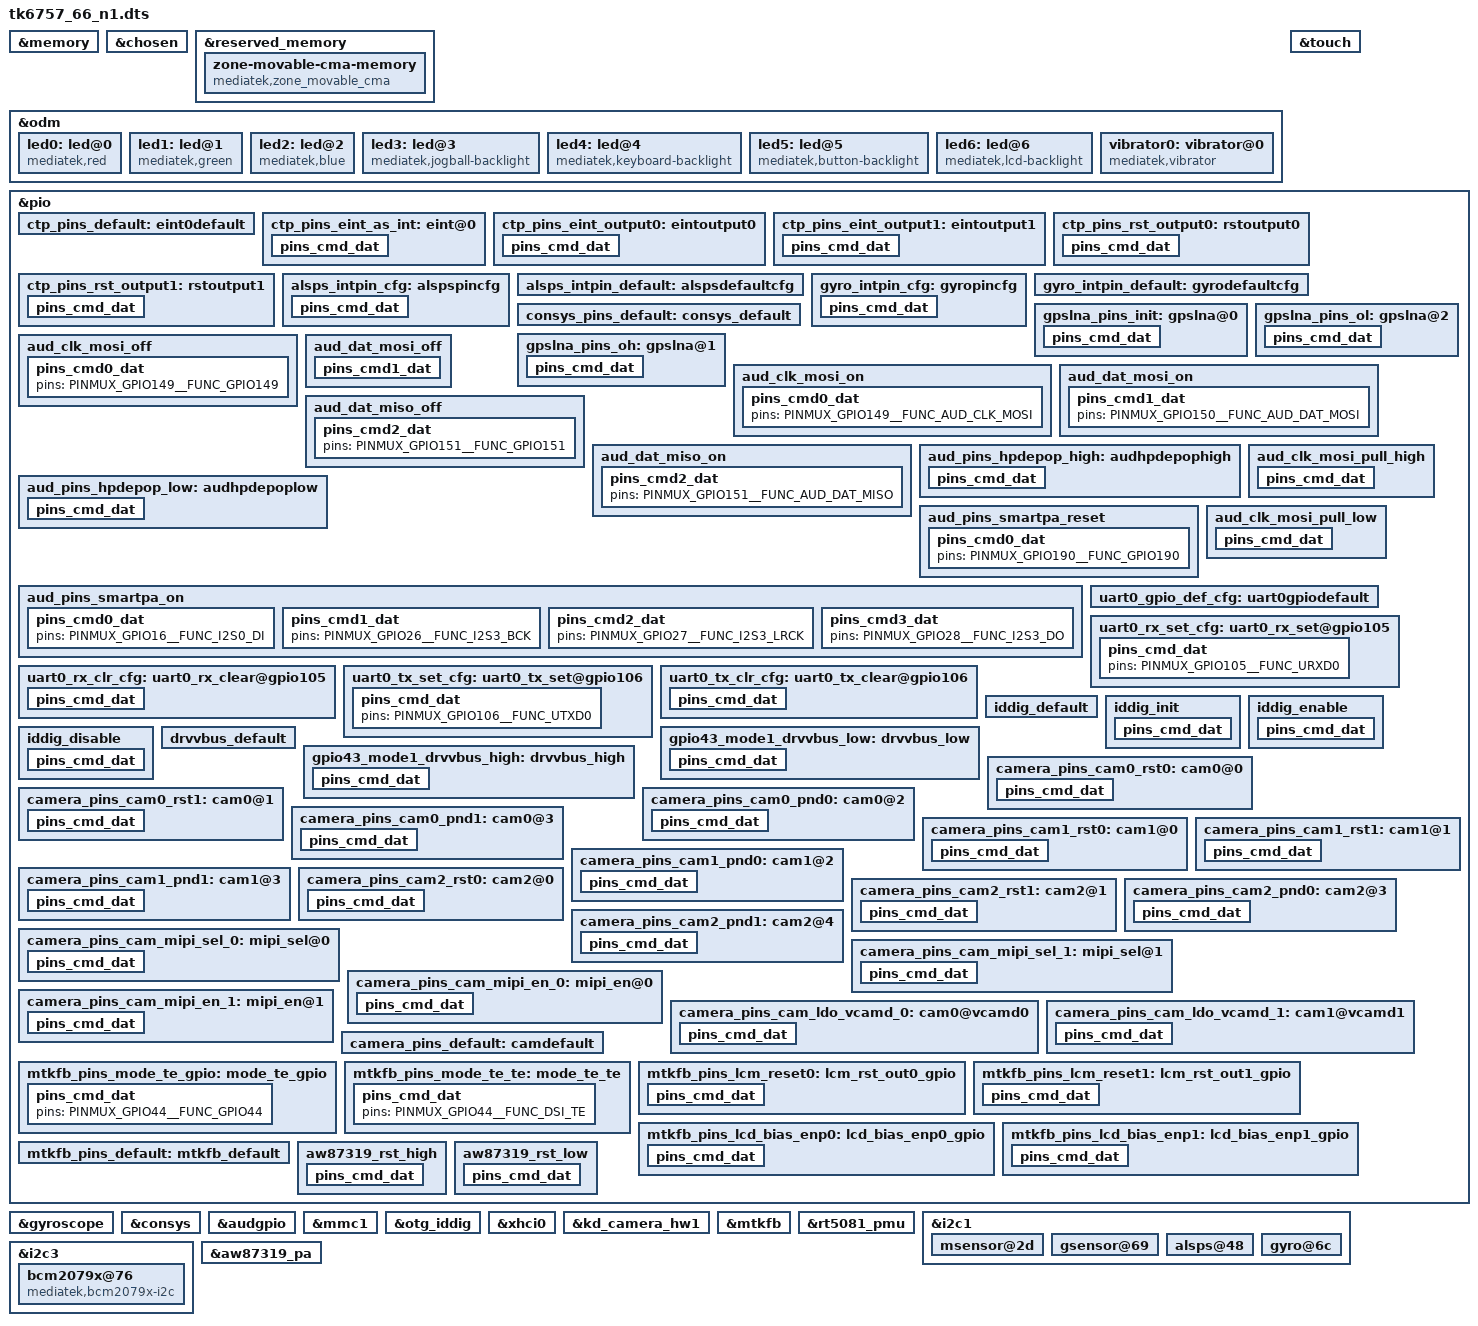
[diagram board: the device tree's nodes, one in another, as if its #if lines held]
#include <generated/autoconf.h>
/dts-v1/;

#ifdef CONFIG_MTK_DTBO_FEATURE
/plugin/;
#include <dt-bindings/interrupt-controller/irq.h>
#include <dt-bindings/interrupt-controller/arm-gic.h>
#include <dt-bindings/mmc/mt6757-msdc.h>
#include <dt-bindings/pinctrl/mt6757-pinfunc.h>
#else
#include "mt6757.dts"
#endif

&memory {
	device_type = "memory";
	reg = <0 0x40000000 0 0x1e605000>,
		  <1 0x00000000 0 0x20000000>;
};

/* chosen */
&chosen {
	bootargs = "console=tty0 console=ttyMT0,921600n1 root=/dev/ram initrd=0x45000000,
	0x1000000 loglevel=8 androidboot.selinux=permissive androidboot.hardware=mt6757";
	/* fpga may has no lk, we need to specify display info here */
	/* fb buffer is reserved using this dts by memory node above */
	atag,videolfb-fb_base_h = <0x0>;
	atag,videolfb-fb_base_l = <0x5e605000>;
	atag,videolfb-islcmfound = <1>;
	/* because no lk, so lcm is not inited */
	atag,videolfb-islcm_inited = <0>;
	atag,videolfb-fps= <6000>;
	atag,videolfb-vramSize= <0x017bb000>;
	atag,videolfb-lcmname= "nt35695_fhd_dsi_cmd_truly_nt50358_drv";
};

&reserved_memory {
	#address-cells = <2>;
	#size-cells = <2>;
	ranges;

	zone-movable-cma-memory {
		compatible = "mediatek,zone_movable_cma";
		size = <0 0xffc00000>;
		/* 256MB alignment */
		alignment = <0 0x10000000>;
		alloc-ranges = <0 0xc0000000 1 0x0>;
	};
};

&odm {
	led0:led@0 {
		compatible = "mediatek,red";
		led_mode = <3>;
		data = <1>;
		pwm_config = <0 0 0 0 0>;
	};
	led1:led@1 {
		compatible = "mediatek,green";
		led_mode = <3>;
		data = <2>;
		pwm_config = <0 0 0 0 0>;
	};
	led2:led@2 {
		compatible = "mediatek,blue";
		led_mode = <0>;
		data = <1>;
		pwm_config = <0 0 0 0 0>;
	};
	led3:led@3 {
		compatible = "mediatek,jogball-backlight";
		led_mode = <0>;
		data = <1>;
		pwm_config = <0 0 0 0 0>;
	};
	led4:led@4 {
		compatible = "mediatek,keyboard-backlight";
		led_mode = <0>;
		data = <1>;
		pwm_config = <0 0 0 0 0>;
	};
	led5:led@5 {
		compatible = "mediatek,button-backlight";
		led_mode = <0>;
		data = <1>;
		pwm_config = <0 0 0 0 0>;
	};
	led6:led@6 {
		compatible = "mediatek,lcd-backlight";
		led_mode = <5>;
		data = <1>;
		pwm_config = <0 0 0 0 0>;
	};
	vibrator0:vibrator@0 {
		compatible = "mediatek,vibrator";
		vib_timer = <25>;
		vib_limit = <9>;
		vib_vol= <9>;
	};


};

/* TOUCH start */
&touch {
	tpd-resolution = <1080 1920>;
	use-tpd-button = <0>;
	tpd-key-num = <3>;
	tpd-key-local = <139 172 158 0>;
	tpd-key-dim-local = <0x5a 0x373 0x64 0x28 0xe6 0x373 0x64 0x28 0x172 0x373 0x64 0x28 0x0 0x0 0x0 0x0>;
	tpd-max-touch-num = <5>;
	tpd-filter-enable = <1>;
	tpd-filter-pixel-density = <146>;
	tpd-filter-custom-prameters = <0 0 0 0 0 0 0 0 0 0 0 0>;
	tpd-filter-custom-speed = <0 0 0>;
	pinctrl-names = "default", "state_eint_as_int", "state_eint_output0", "state_eint_output1",
		"state_rst_output0", "state_rst_output1";
	pinctrl-0 = <&ctp_pins_default>;
	pinctrl-1 = <&ctp_pins_eint_as_int>;
	pinctrl-2 = <&ctp_pins_eint_output0>;
	pinctrl-3 = <&ctp_pins_eint_output1>;
	pinctrl-4 = <&ctp_pins_rst_output0>;
	pinctrl-5 = <&ctp_pins_rst_output1>;
	status = "okay";
};
&pio {
	ctp_pins_default: eint0default {
	};
	ctp_pins_eint_as_int: eint@0 {
		pins_cmd_dat {
			pins = <PINMUX_GPIO1__FUNC_GPIO1>;
			slew-rate = <0>;
			bias-disable;
		};
	};
	ctp_pins_eint_output0: eintoutput0 {
		pins_cmd_dat {
			pins = <PINMUX_GPIO1__FUNC_GPIO1>;
			slew-rate = <1>;
			output-low;
		};
	};
	ctp_pins_eint_output1: eintoutput1 {
		pins_cmd_dat {
			pins = <PINMUX_GPIO1__FUNC_GPIO1>;
			slew-rate = <1>;
			output-high;
		};
	};
	ctp_pins_rst_output0: rstoutput0 {
		pins_cmd_dat {
			pins = <PINMUX_GPIO42__FUNC_GPIO42>;
			slew-rate = <1>;
			output-low;
		};
	};
	ctp_pins_rst_output1: rstoutput1 {
		pins_cmd_dat {
			pins = <PINMUX_GPIO42__FUNC_GPIO42>;
			slew-rate = <1>;
			output-high;
		};
	};
};
/* TOUCH end */

/* sensor gpio standization */
&pio {
	alsps_intpin_cfg: alspspincfg {

		pins_cmd_dat {
			pins = <PINMUX_GPIO2__FUNC_GPIO2>;
			slew-rate = <0>;
			bias-pull-up = <0>;
		};
	};

	alsps_intpin_default: alspsdefaultcfg {

	};

	gyro_intpin_cfg: gyropincfg {

		pins_cmd_dat {
			pins = <PINMUX_GPIO0__FUNC_GPIO0>;
			slew-rate = <0>;
			bias-pull-down = <0>;
		};
	};

	gyro_intpin_default: gyrodefaultcfg {

	};
};


&gyroscope {
	pinctrl-names = "pin_default", "pin_cfg";
	pinctrl-0 = <&gyro_intpin_default>;
	pinctrl-1 = <&gyro_intpin_cfg>;
	status = "okay";
};
/* sensor end */

/* CONSYS GPIO standardization */
&pio {
	consys_pins_default: consys_default {
	};
	gpslna_pins_init: gpslna@0 {
		pins_cmd_dat {
			pins = <PINMUX_GPIO114__FUNC_GPIO114>;
			slew-rate = <0>;
			bias-disable;
			output-low;
		};
	};
	gpslna_pins_oh: gpslna@1 {
		pins_cmd_dat {
			pins = <PINMUX_GPIO114__FUNC_GPIO114>;
			slew-rate = <1>;
			output-high;
		};
	};
	gpslna_pins_ol: gpslna@2 {
		pins_cmd_dat {
			pins = <PINMUX_GPIO114__FUNC_GPIO114>;
			slew-rate = <1>;
			output-low;
		};
	};
};
&consys {
	pinctrl-names = "default", "gps_lna_state_init", "gps_lna_state_oh", "gps_lna_state_ol";
	pinctrl-0 = <&consys_pins_default>;
	pinctrl-1 = <&gpslna_pins_init>;
	pinctrl-2 = <&gpslna_pins_oh>;
	pinctrl-3 = <&gpslna_pins_ol>;
	status = "okay";
};
/* CONSYS end */

/* AUDIO GPIO standardization */
&audgpio {
	pinctrl-names = "aud_clk_mosi_off",
			"aud_clk_mosi_on",
			"aud_dat_mosi_off",
			"aud_dat_mosi_on",
			"aud_dat_miso_off",
			"aud_dat_miso_on",
			"hpdepop-pullhigh",
			"hpdepop-pulllow",
			"aud_smartpa_reset",
			"aud_smartpa_on",
			"aud_clk_mosi_pull_high",
			"aud_clk_mosi_pull_low";
	pinctrl-0 = <&aud_clk_mosi_off>;
	pinctrl-1 = <&aud_clk_mosi_on>;
	pinctrl-2 = <&aud_dat_mosi_off>;
	pinctrl-3 = <&aud_dat_mosi_on>;
	pinctrl-4 = <&aud_dat_miso_off>;
	pinctrl-5 = <&aud_dat_miso_on>;
	pinctrl-6 = <&aud_pins_hpdepop_high>;
	pinctrl-7 = <&aud_pins_hpdepop_low>;
	pinctrl-8 = <&aud_pins_smartpa_reset>;
	pinctrl-9 = <&aud_pins_smartpa_on>;
	pinctrl-10 = <&aud_clk_mosi_pull_high>;
	pinctrl-11 = <&aud_clk_mosi_pull_low>;
	status = "okay";
};

&pio {
	aud_clk_mosi_off: aud_clk_mosi_off {
		pins_cmd0_dat {
			pins = <PINMUX_GPIO149__FUNC_GPIO149>;
		};
	};

	aud_clk_mosi_on: aud_clk_mosi_on {
		pins_cmd0_dat {
			pins = <PINMUX_GPIO149__FUNC_AUD_CLK_MOSI>;
		};
	};

	aud_dat_mosi_off: aud_dat_mosi_off {
		pins_cmd1_dat {
			pins = <PINMUX_GPIO150__FUNC_GPIO150>;
			slew-rate = <0>;
			bias-pull-up = <0>;
		};
	};

	aud_dat_mosi_on: aud_dat_mosi_on {
		pins_cmd1_dat {
			pins = <PINMUX_GPIO150__FUNC_AUD_DAT_MOSI>;
		};
	};

	aud_dat_miso_off: aud_dat_miso_off {
		pins_cmd2_dat {
			pins = <PINMUX_GPIO151__FUNC_GPIO151>;
		};
	};

	aud_dat_miso_on: aud_dat_miso_on {
		pins_cmd2_dat {
			pins = <PINMUX_GPIO151__FUNC_AUD_DAT_MISO>;
		};
	};

	aud_pins_hpdepop_high: audhpdepophigh {
		pins_cmd_dat {
			pins = <PINMUX_GPIO24__FUNC_GPIO24>;
			slew-rate = <1>;
			output-high;
		};
	};

	aud_pins_hpdepop_low: audhpdepoplow {
		pins_cmd_dat {
			pins = <PINMUX_GPIO24__FUNC_GPIO24>;
			slew-rate = <1>;
			output-low;
		};
	};

	aud_pins_smartpa_reset: aud_pins_smartpa_reset {
		pins_cmd0_dat {
			pins = <PINMUX_GPIO190__FUNC_GPIO190>;
		};
	};

	aud_pins_smartpa_on: aud_pins_smartpa_on {
		pins_cmd0_dat {
			pins = <PINMUX_GPIO16__FUNC_I2S0_DI>;
		};
		pins_cmd1_dat {
			pins = <PINMUX_GPIO26__FUNC_I2S3_BCK>;
		};
		pins_cmd2_dat {
			pins = <PINMUX_GPIO27__FUNC_I2S3_LRCK>;
		};
		pins_cmd3_dat {
			pins = <PINMUX_GPIO28__FUNC_I2S3_DO>;
		};
	};

	aud_clk_mosi_pull_high: aud_clk_mosi_pull_high {
		pins_cmd_dat {
			pins = <PINMUX_GPIO149__FUNC_GPIO149>;
			slew-rate = <1>;
			output-high;
		};
	};

	aud_clk_mosi_pull_low: aud_clk_mosi_pull_low {
		pins_cmd_dat {
			pins = <PINMUX_GPIO149__FUNC_GPIO149>;
			slew-rate = <1>;
			output-low;
		};
	};
};
/* AUDIO end */

&mmc1 {
	status = "okay";
};

/* UART GPIO */
/*
*&apuart0 {
*	pinctrl-names = "uart0_gpio_default",
*			"uart0_rx_set",
*			"uart0_rx_clear",
*			"uart0_tx_set",
*			"uart0_tx_clear";
*	pinctrl-0 = <&uart0_gpio_def_cfg>;
*	pinctrl-1 = <&uart0_rx_set_cfg>;
*	pinctrl-2 = <&uart0_rx_clr_cfg>;
*	pinctrl-3 = <&uart0_tx_set_cfg>;
*	pinctrl-4 = <&uart0_tx_clr_cfg>;
*	status = "okay";
*};
*/
&pio {
	/* UART GPIO Settings - Start */
	/* UART0: rx set, rx clear, tx clear, tx clear*/
	uart0_gpio_def_cfg:uart0gpiodefault {

	};
	uart0_rx_set_cfg:uart0_rx_set@gpio105 {
		pins_cmd_dat {
			pins = <PINMUX_GPIO105__FUNC_URXD0>;
		};
	};
	uart0_rx_clr_cfg:uart0_rx_clear@gpio105  {
		pins_cmd_dat {
			pins = <PINMUX_GPIO105__FUNC_GPIO105>;
			slew-rate = <1>;
			output-high;
		};
	};
	uart0_tx_set_cfg:uart0_tx_set@gpio106  {
		pins_cmd_dat {
			pins = <PINMUX_GPIO106__FUNC_UTXD0>;
		};
	};
	uart0_tx_clr_cfg:uart0_tx_clear@gpio106  {
		pins_cmd_dat {
			pins = <PINMUX_GPIO106__FUNC_GPIO106>;
			slew-rate = <1>;
			output-high;
		};
	};
};/* UART GPIO end */

&pio {
	iddig_default: iddig_default {
	};
	iddig_init: iddig_init {
		pins_cmd_dat {
			pins = <PINMUX_GPIO42__FUNC_IDDIG>;
			input-enable;
			slew-rate = <0>;
			bias-pull-up = <0>;
		};
	};
	iddig_enable: iddig_enable {
		pins_cmd_dat {
			pins = <PINMUX_GPIO42__FUNC_IDDIG>;
			input-enable;
			slew-rate = <0>;
			bias-pull-up = <0>;
		};
	};
	iddig_disable: iddig_disable {
		pins_cmd_dat {
			pins = <PINMUX_GPIO42__FUNC_GPIO42>;
			input-disable;
			slew-rate = <1>;
			output-low;
		};
	};
};

&pio {
	drvvbus_default: drvvbus_default {
	};

	gpio43_mode1_drvvbus_low: drvvbus_low {
		pins_cmd_dat {
			pins = <PINMUX_GPIO43__FUNC_USB_DRVVBUS>;
			slew-rate = <1>;
			output-low;
		};
	};

	gpio43_mode1_drvvbus_high: drvvbus_high {
		pins_cmd_dat {
			pins = <PINMUX_GPIO43__FUNC_USB_DRVVBUS>;
			slew-rate = <1>;
			output-high;
		};
	};
};

&otg_iddig {
	pinctrl-names = "iddig_default", "iddig_init", "iddig_enable", "iddig_disable";
	pinctrl-0 = <&iddig_default>;
	pinctrl-1 = <&iddig_init>;
	pinctrl-2 = <&iddig_enable>;
	pinctrl-3 = <&iddig_disable>;
	status = "okay";
};

&xhci0 {
	pinctrl-names = "drvvbus_default", "drvvbus_low", "drvvbus_high";
	pinctrl-0 = <&drvvbus_default>;
	pinctrl-1 = <&gpio43_mode1_drvvbus_low>;
	pinctrl-2 = <&gpio43_mode1_drvvbus_high>;
	status = "okay";
};
/* CAMERA GPIO standardization */
&pio {
	camera_pins_cam0_rst0: cam0@0 {
		pins_cmd_dat {
			pins = <PINMUX_GPIO110__FUNC_GPIO110>;
			slew-rate = <1>; /*direction 0:in, 1:out*/
			output-low;/*direction out used only. output_low or high*/
		};
	};
	camera_pins_cam0_rst1: cam0@1 {
		pins_cmd_dat {
			pins = <PINMUX_GPIO110__FUNC_GPIO110>;
			slew-rate = <1>;
			output-high;
		};
	};
	camera_pins_cam0_pnd0: cam0@2 {
		pins_cmd_dat {
			pins = <PINMUX_GPIO107__FUNC_GPIO107>;
			slew-rate = <1>;
			output-low;
		};
	};
	camera_pins_cam0_pnd1: cam0@3 {
		pins_cmd_dat {
			pins = <PINMUX_GPIO107__FUNC_GPIO107>;
			slew-rate = <1>;
			output-high;
		};
	};
	camera_pins_cam1_rst0: cam1@0 {
		pins_cmd_dat {
			pins = <PINMUX_GPIO111__FUNC_GPIO111>;
			slew-rate = <1>; /*direction 0:in, 1:out*/
			output-low;/*direction out used only. output_low or high*/
		};
	};
	camera_pins_cam1_rst1: cam1@1 {
		pins_cmd_dat {
			pins = <PINMUX_GPIO111__FUNC_GPIO111>;
			slew-rate = <1>;
			output-high;
		};
	};
	camera_pins_cam1_pnd0: cam1@2 {
		pins_cmd_dat {
			pins = <PINMUX_GPIO108__FUNC_GPIO108>;
			slew-rate = <1>;
			output-low;
		};
	};
	camera_pins_cam1_pnd1: cam1@3 {
		pins_cmd_dat {
			pins = <PINMUX_GPIO108__FUNC_GPIO108>;
			slew-rate = <1>;
			output-high;
		};
	};
	camera_pins_cam2_rst0: cam2@0 {
		pins_cmd_dat {
			pins = <PINMUX_GPIO87__FUNC_GPIO87>;
			slew-rate = <1>;
			output-low;
		};
	};
	camera_pins_cam2_rst1: cam2@1 {
		pins_cmd_dat {
			pins = <PINMUX_GPIO87__FUNC_GPIO87>;
			slew-rate = <1>;
			output-high;
		};
	};
	camera_pins_cam2_pnd0: cam2@3 {
		pins_cmd_dat {
			pins = <PINMUX_GPIO85__FUNC_GPIO85>;
			slew-rate = <1>;
			output-low;
		};
	};
	camera_pins_cam2_pnd1: cam2@4 {
		pins_cmd_dat {
			pins = <PINMUX_GPIO85__FUNC_GPIO85>;
			slew-rate = <1>;
			output-high;
		};
	};
	camera_pins_cam_mipi_sel_0: mipi_sel@0 {
		pins_cmd_dat {
			pins = <PINMUX_GPIO102__FUNC_GPIO102>;
			slew-rate = <1>;
			output-low;
		};
	};
	camera_pins_cam_mipi_sel_1: mipi_sel@1 {
		pins_cmd_dat {
			pins = <PINMUX_GPIO102__FUNC_GPIO102>;
			slew-rate = <1>;
			output-high;
		};
	};
	camera_pins_cam_mipi_en_0: mipi_en@0 {
		pins_cmd_dat {
			pins = <PINMUX_GPIO10__FUNC_GPIO10>;
			slew-rate = <1>;
			output-low;
		};
	};
	camera_pins_cam_mipi_en_1: mipi_en@1 {
		pins_cmd_dat {
			pins = <PINMUX_GPIO10__FUNC_GPIO10>;
			slew-rate = <1>;
			output-high;
		};
	};
	camera_pins_cam_ldo_vcamd_0: cam0@vcamd0 {
		pins_cmd_dat {
			pins = <PINMUX_GPIO100__FUNC_GPIO100>;
			slew-rate = <1>;
			output-low;
		};
	};
	camera_pins_cam_ldo_vcamd_1: cam1@vcamd1 {
		pins_cmd_dat {
			pins = <PINMUX_GPIO100__FUNC_GPIO100>;
			slew-rate = <1>;
			output-high;
		};
	};
	camera_pins_default: camdefault {
	};

};

&kd_camera_hw1 {
	pinctrl-names = "default",
			"cam0_rst0", "cam0_rst1", "cam0_pnd0", "cam0_pnd1",
			"cam1_rst0", "cam1_rst1", "cam1_pnd0", "cam1_pnd1",
			"cam2_rst0", "cam2_rst1", "cam2_pnd0", "cam2_pnd1",
			"cam_mipi_switch_sel_0", "cam_mipi_switch_sel_1",
			"cam_mipi_switch_en_0", "cam_mipi_switch_en_1",
			"cam_ldo_vcamd_0", "cam_ldo_vcamd_1";

	pinctrl-0 = <&camera_pins_default>;
	pinctrl-1 = <&camera_pins_cam0_rst0>;
	pinctrl-2 = <&camera_pins_cam0_rst1>;
	pinctrl-3 = <&camera_pins_cam0_pnd0>;
	pinctrl-4 = <&camera_pins_cam0_pnd1>;
	pinctrl-5 = <&camera_pins_cam1_rst0>;
	pinctrl-6 = <&camera_pins_cam1_rst1>;
	pinctrl-7 = <&camera_pins_cam1_pnd0>;
	pinctrl-8 = <&camera_pins_cam1_pnd1>;
	pinctrl-9 = <&camera_pins_cam2_rst0>;
	pinctrl-10 = <&camera_pins_cam2_rst1>;
	pinctrl-11 = <&camera_pins_cam2_pnd0>;
	pinctrl-12 = <&camera_pins_cam2_pnd1>;
	pinctrl-13 = <&camera_pins_cam_mipi_sel_0>;
	pinctrl-14 = <&camera_pins_cam_mipi_sel_1>;
	pinctrl-15 = <&camera_pins_cam_mipi_en_0>;
	pinctrl-16 = <&camera_pins_cam_mipi_en_1>;
	pinctrl-17 = <&camera_pins_cam_ldo_vcamd_0>;
	pinctrl-18 = <&camera_pins_cam_ldo_vcamd_1>;
	status = "okay";

};
/* CAMERA GPIO end */

/* DISPSYS GPIO standardization */
&pio {

	mtkfb_pins_mode_te_gpio: mode_te_gpio {
		pins_cmd_dat {
			pins = <PINMUX_GPIO44__FUNC_GPIO44>;
		};
	};

	mtkfb_pins_mode_te_te: mode_te_te {
		pins_cmd_dat {
			pins = <PINMUX_GPIO44__FUNC_DSI_TE>;
		};
	};

	mtkfb_pins_lcm_reset0: lcm_rst_out0_gpio {
		pins_cmd_dat {
			pins = <PINMUX_GPIO158__FUNC_LCM_RST>;
			slew-rate = <1>;
			output-low;
		};
	};

	mtkfb_pins_lcm_reset1: lcm_rst_out1_gpio {
		pins_cmd_dat {
			pins = <PINMUX_GPIO158__FUNC_LCM_RST>;
			slew-rate = <1>;
			output-high;
		};
	};

	mtkfb_pins_lcd_bias_enp0: lcd_bias_enp0_gpio {
		pins_cmd_dat {
			pins = <PINMUX_GPIO21__FUNC_GPIO21>;
			slew-rate = <1>;
			output-low;
		};
	};

	mtkfb_pins_lcd_bias_enp1: lcd_bias_enp1_gpio {
		pins_cmd_dat {
			pins = <PINMUX_GPIO21__FUNC_GPIO21>;
			slew-rate = <1>;
			output-high;
		};
	};

	mtkfb_pins_default: mtkfb_default {
	};

};

&mtkfb {
	pinctrl-names = "default", "mode_te_gpio", "mode_te_te", "lcm_rst_out0_gpio",
					"lcm_rst_out1_gpio", "lcd_bias_enp0_gpio", "lcd_bias_enp1_gpio";
	pinctrl-0 = <&mtkfb_pins_default>;
	pinctrl-1 = <&mtkfb_pins_mode_te_gpio>;
	pinctrl-2 = <&mtkfb_pins_mode_te_te>;
	pinctrl-3 = <&mtkfb_pins_lcm_reset0>;
	pinctrl-4 = <&mtkfb_pins_lcm_reset1>;
	pinctrl-5 = <&mtkfb_pins_lcd_bias_enp0>;
	pinctrl-6 = <&mtkfb_pins_lcd_bias_enp1>;
	partial-update = <1>;
	status = "okay";
};/* DISPSYS GPIO standardization end */

&rt5081_pmu {
	rt,intr_gpio_num = <101>; /* direct defined GPIO num */
	rt,intr_gpio = <&pio 101 0x0>;
};

&i2c1 {
	msensor@2d {
		i2c_num = <1>;
		i2c_addr = <0x2d 0 0 0>;
		direction = <3>;
		power_id = <0xffff>;
		power_vol = <0>;
		is_batch_supported = <0>;
	};

	gsensor@69 {
		i2c_num	= <1>;
		i2c_addr = <0x69 0 0 0>;
		direction = <3>;
		power_id = <0xffff>;
		power_vol = <0>;
		firlen = <16>;
		is_batch_supported = <1>;
	};
	
	alsps@48 {
		pinctrl-names = "pin_default", "pin_cfg";
		pinctrl-0 = <&alsps_intpin_default>;
		pinctrl-1 = <&alsps_intpin_cfg>;
		status = "okay";
		i2c_num = <1>;
		i2c_addr = <0x48 0 0 0>;
		polling_mode_ps = <0>;
		polling_mode_als = <1>;
		power_id = <0xffff>;
		power_vol = <0>;
		als_level = <0x5 0x9 0x24 0x3b 0x52 0x84 0xcd 0x111 0x1f4 0x34d 0x470 0x609 0x93c 0x122f 0x1b46>;
		als_value = <0x0 0xa 0x50 0x55 0x5a 0x91 0xe1 0x12c 0x226 0x3a2 0x4e2 0x6a4 0xa28 0x1400 0x1e00 0x2800>;
		ps_threshold_high = <0x6a4>;
		ps_threshold_low = <0x5dc>;
		is_batch_supported_ps = <0x0>;
		is_batch_supported_als = <0x0>;
	};

	gyro@6c {
		pinctrl-names = "pin_default", "pin_cfg";
		pinctrl-0 = <&gyro_intpin_default>;
		pinctrl-1 = <&gyro_intpin_cfg>;
		status = "okay";
		/* customization */
		i2c_num = <1>;
		i2c_addr = <0x6c 0 0 0>;
		direction = <3>;
		power_id = <0xffff>;
		power_vol = <0>;
		firlen = <0>;
		is_batch_supported = <0>;
	};
};

&i2c3 {
	bcm2079x@76 {
		reg = <0x76>;
		compatible = "mediatek,bcm2079x-i2c";
		interrupt-parent = <0x10>;
		interrupts = <0x52 0x8>;
		debounce = <0x52 0x0>;
		en-gpio = <&pio 15 0>;
		wake-gpio = <&pio 25 0>;
		irq-gpio = <&pio 13 0>;
		status = "okay";
	};
};

&aw87319_pa {
	pinctrl-names = "aw87319_rst_high", "aw87319_rst_low";
	pinctrl-0 = <&aw87319_rst_high>;
	pinctrl-1 = <&aw87319_rst_low>;
	status = "okay";
};

&pio {
    aw87319_rst_high: aw87319_rst_high{
        pins_cmd_dat {
            pins = <PINMUX_GPIO55__FUNC_GPIO55>;
            slew-rate = <1>;
            output-high;
        };
    };

    aw87319_rst_low: aw87319_rst_low{
        pins_cmd_dat {
            pins = <PINMUX_GPIO55__FUNC_GPIO55>;
            slew-rate = <1>;
            output-low;
        };
    };
};

#include <tk6757_66_n1/cust.dtsi>
/*End of this file, DO NOT ADD ANYTHING HERE*/
